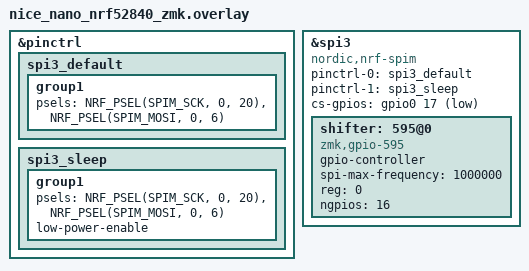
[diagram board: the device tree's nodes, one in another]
&pinctrl {
    spi3_default: spi3_default {
        group1 {
            psels = <NRF_PSEL(SPIM_SCK, 0, 20)>,
                    <NRF_PSEL(SPIM_MOSI, 0, 6)>;
        };
    };

    spi3_sleep: spi3_sleep {
        group1 {
            psels = <NRF_PSEL(SPIM_SCK, 0, 20)>,
                    <NRF_PSEL(SPIM_MOSI, 0, 6)>;
            low-power-enable;
        };
    };
};

&spi3 {
    compatible = "nordic,nrf-spim";
    status = "okay";
    pinctrl-0 = <&spi3_default>;
    pinctrl-1 = <&spi3_sleep>;
    pinctrl-names = "default", "sleep";
    cs-gpios = <&gpio0 17 GPIO_ACTIVE_LOW>;

    shifter: 595@0 {
        compatible = "zmk,gpio-595";
        status = "okay";
        gpio-controller;
        spi-max-frequency = <1000000>;
        reg = <0>;
        #gpio-cells = <2>;
        ngpios = <16>;
    };
};
